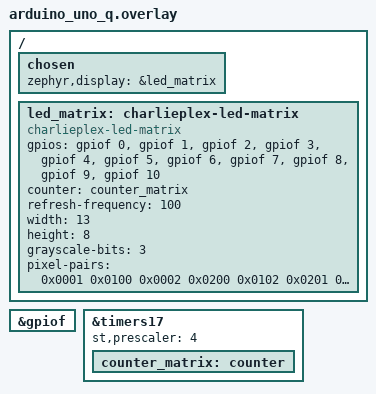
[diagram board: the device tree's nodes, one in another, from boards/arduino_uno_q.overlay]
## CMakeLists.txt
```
cmake_minimum_required(VERSION 3.20.0)

find_package(Zephyr REQUIRED HINTS $ENV{ZEPHYR_BASE})
project(led_matrix)

target_sources(app PRIVATE src/main.c)
```

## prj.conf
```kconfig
# LED matrix demo for the UNO Q via the charlieplex display driver.
CONFIG_GPIO=y
CONFIG_COUNTER=y
CONFIG_DISPLAY=y
CONFIG_CHARLIEPLEX_LED_MATRIX=y
CONFIG_LOG=y
CONFIG_MAIN_STACK_SIZE=2048
```

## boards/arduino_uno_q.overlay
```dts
/*
 * Arduino UNO Q (STM32U585) LED matrix enablement for the charlieplex display
 * driver.
 *
 * The 13x8 = 104-LED matrix is charlieplexed across STM32 port F lines PF0..PF10
 * (11 lines). A hardware timer (TIM17) scans the pixels for persistence of
 * vision. The pixel-pairs below is the LED index -> {high,low} pin-pair table
 * lifted from Arduino's ArduinoCore-zephyr loader/matrix.inc, encoded as
 * (high << 8) | low where the indices are positions in the gpios list
 * (gpios[0]=PF0 ... gpios[10]=PF10).
 *
 * Framebuffer order == LED index order (row-major as the panel is wired); the
 * 13x8 logical geometry and any rotation is handled in application code.
 */

/ {
	chosen {
		zephyr,display = &led_matrix;
	};

	led_matrix: charlieplex-led-matrix {
		compatible = "charlieplex-led-matrix";
		gpios = <&gpiof 0 0>, <&gpiof 1 0>, <&gpiof 2 0>,
			<&gpiof 3 0>, <&gpiof 4 0>, <&gpiof 5 0>,
			<&gpiof 6 0>, <&gpiof 7 0>, <&gpiof 8 0>,
			<&gpiof 9 0>, <&gpiof 10 0>;
		counter = <&counter_matrix>;
		refresh-frequency = <100>;
		width = <13>;
		height = <8>;
		grayscale-bits = <3>;
		pixel-pairs = <
			0x0001 0x0100 0x0002 0x0200 0x0102 0x0201 0x0003 0x0300 0x0103 0x0301
			0x0203 0x0302 0x0004 0x0400 0x0104 0x0401 0x0204 0x0402 0x0304 0x0403
			0x0005 0x0500 0x0105 0x0501 0x0205 0x0502 0x0305 0x0503 0x0405 0x0504
			0x0006 0x0600 0x0106 0x0601 0x0206 0x0602 0x0306 0x0603 0x0406 0x0604
			0x0506 0x0605 0x0007 0x0700 0x0107 0x0701 0x0207 0x0702 0x0307 0x0703
			0x0407 0x0704 0x0507 0x0705 0x0607 0x0706 0x0008 0x0800 0x0108 0x0801
			0x0208 0x0802 0x0308 0x0803 0x0408 0x0804 0x0508 0x0805 0x0608 0x0806
			0x0708 0x0807 0x0009 0x0900 0x0109 0x0901 0x0209 0x0902 0x0309 0x0903
			0x0409 0x0904 0x0509 0x0905 0x0609 0x0906 0x0709 0x0907 0x0809 0x0908
			0x000a 0x0a00 0x010a 0x0a01 0x020a 0x0a02 0x030a 0x0a03 0x040a 0x0a04
			0x050a 0x0a05 0x060a 0x0a06
		>;
	};
};

&gpiof {
	status = "okay";
};

&timers17 {
	status = "okay";
	st,prescaler = <4>;

	counter_matrix: counter {
		status = "okay";
	};
};
```

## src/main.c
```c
/*
 * LED matrix demo for the Arduino UNO Q (STM32U585) using the charlieplex
 * display driver via the standard Zephyr display API.
 *
 * Walks a single lit pixel across the 13x8 matrix, then flashes the whole
 * panel, using display_write() with a MONO01 buffer. A green-LED heartbeat
 * runs independently so firmware liveness is visible even if the matrix path
 * misbehaves.
 *
 * Verification when hardware is connected: the moving dot proves per-pixel
 * addressing + the framebuffer->pin-pair mapping; the full-panel flash proves
 * the scan/refresh covers all 104 LEDs.
 */

#include <zephyr/kernel.h>
#include <zephyr/device.h>
#include <zephyr/drivers/display.h>
#include <zephyr/drivers/gpio.h>
#include <zephyr/logging/log.h>
#include <string.h>

LOG_MODULE_REGISTER(led_matrix_demo, LOG_LEVEL_INF);

#define W 13
#define H 8
#define STRIDE ((W + 7) / 8)          /* bytes per row, MONO01 bit-packed */

static const struct device *const disp = DEVICE_DT_GET(DT_CHOSEN(zephyr_display));
static const struct gpio_dt_spec led =
	GPIO_DT_SPEC_GET_OR(DT_ALIAS(led0), gpios, {0});

static uint8_t buf[STRIDE * H];

static void set_px(uint8_t *b, int x, int y, bool on)
{
	if (x < 0 || x >= W || y < 0 || y >= H) {
		return;
	}
	uint8_t *byte = &b[y * STRIDE + (x / 8)];

	if (on) {
		*byte |= BIT(x % 8);
	} else {
		*byte &= ~BIT(x % 8);
	}
}

static void push(void)
{
	struct display_buffer_descriptor desc = {
		.buf_size = sizeof(buf),
		.width = W,
		.height = H,
		.pitch = STRIDE * 8,          /* pitch is in pixels */
		.frame_incomplete = false,
	};

	display_write(disp, 0, 0, &desc, buf);
}

static void heartbeat(void)
{
	if (!gpio_is_ready_dt(&led)) {
		return;
	}
	gpio_pin_configure_dt(&led, GPIO_OUTPUT_INACTIVE);
	while (1) {
		gpio_pin_toggle_dt(&led);
		k_sleep(K_MSEC(500));
	}
}
K_THREAD_DEFINE(hb_tid, 512, heartbeat, NULL, NULL, NULL, 7, 0, 0);

int main(void)
{
	if (!device_is_ready(disp)) {
		LOG_ERR("display not ready");
		return -1;
	}

	struct display_capabilities caps;

	display_get_capabilities(disp, &caps);
	LOG_INF("matrix %ux%u up", caps.x_resolution, caps.y_resolution);

	display_blanking_off(disp);

	while (1) {
		/* Walking dot across all 104 cells. */
		for (int y = 0; y < H; y++) {
			for (int x = 0; x < W; x++) {
				memset(buf, 0, sizeof(buf));
				set_px(buf, x, y, true);
				push();
				k_sleep(K_MSEC(40));
			}
		}

		/* Whole panel on, then off. */
		memset(buf, 0xFF, sizeof(buf));
		push();
		k_sleep(K_MSEC(600));
		memset(buf, 0, sizeof(buf));
		push();
		k_sleep(K_MSEC(400));
	}

	return 0;
}
```
